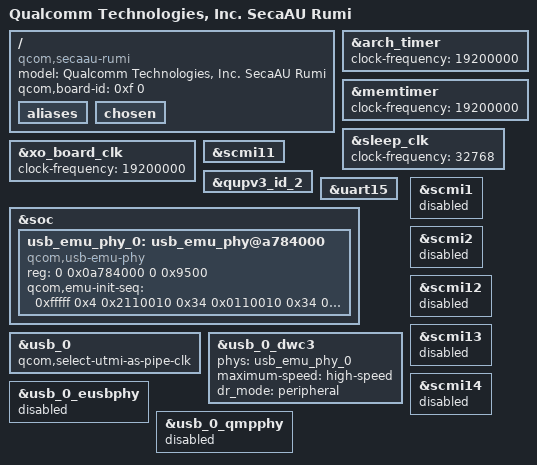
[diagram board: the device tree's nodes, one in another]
// SPDX-License-Identifier: BSD-3-Clause
/*
 * Copyright (c) Qualcomm Technologies, Inc. and/or its subsidiaries.
 */

/dts-v1/;

#include "seca.dtsi"
#include "seca-pinctrl.dtsi"

/ {
	model = "Qualcomm Technologies, Inc. SecaAU Rumi";
	compatible = "qcom,secaau-rumi", "qcom,seca";
	qcom,board-id = <0xf 0>;
	aliases { };
	chosen { };
};

&arch_timer {
	clock-frequency = <19200000>;
};

&memtimer {
	clock-frequency = <19200000>;
};

&sleep_clk {
	clock-frequency = <32768>;
};

&xo_board_clk {
	clock-frequency = <19200000>;
};

&scmi11 {
	status = "okay";
};

&qupv3_id_2 {
	status = "okay";
};

&uart15 {
	status = "okay";
};

&soc {

	usb_emu_phy_0: usb_emu_phy@a784000 {
		compatible = "qcom,usb-emu-phy";
		reg = <0 0x0a784000 0 0x9500>;

		#phy-cells = <0>;

		qcom,emu-init-seq = <0xfffff 0x4
				     0x2110010 0x34
				     0x0110010 0x34
				     0xffff3 0x4
				     0xffff0 0x4
				     0x100000 0x20
				     0x0 0x20
				     0x1A0 0x20
				     0x100000 0x3c
				     0x0 0x3c
				     0x10060 0x3c
				     0x0 0x4
				     0x9 0x14>;
	};
};

&usb_0 {
	qcom,select-utmi-as-pipe-clk;
	status = "okay";
};

&usb_0_dwc3 {
	phys = <&usb_emu_phy_0>;
	phy-names = "usb2-phy";
	maximum-speed = "high-speed";
	dr_mode = "peripheral";
	/delete-property/ usb-role-switch;

	status = "okay";
};

&scmi1 {
	status = "disabled";
};

&scmi2 {
	status = "disabled";
};

&scmi12 {
	status = "disabled";
};

&scmi13 {
	status = "disabled";
};

&scmi14 {
	status = "disabled";
};

&usb_0_eusbphy {
	status = "disabled";
};

&usb_0_qmpphy {
	status = "disabled";
};
